# LPC12D27 register map
File version: 3
Registers are 32-bit, read-write, reset 0x0 unless marked. A register's access mark holds for its fields unless they carry their own. Offsets are from the block's base; [hi:lo] are bit positions; {n}, {i} and the like mark numbered series; 'fields as' and 'values as' point back to an identical list.

## RTC — Product name title=UM10441 Chapter title=LPC122x Real-Time Clock (RTC) Modification date=2/11/2011 Major revision=1 Minor revision=0
Base 0x40050000
0x00 DR ro — Data register
  [31:0] DATA — Returns the current RTC value.
0x04 MR — Match register
  [31:0] MATCH — RTC match register value.
0x08 LR — Load register
  [31:0] LOAD — RTC load register value.
0x0C CR — Control register
  [0] RTCSTART — Enables the RTC. Once the RTC is enabled through this bit, any writes to this bit have no effect on the RTC until a system reset.
    0=RTC_DISABLED_; 1=RTC_ENABLED_
0x10 ICSC — Interrupt control set/clear register
  [0] RTCIC — Interrupt control register. A read returns the current value of the RTC control register.
    0=MASK (Writing 0 masks the interrupt.); 1=ENABLE (Writing 1 enables the interrupt.)
0x14 RIS ro — Raw interrupt status register
  [0] RTCRIS — Raw interrupt event flag register. A read returns the state of the raw interrupt event flag.
0x18 MIS ro — Masked interrupt status register
  [0] RTCMIS — Masked interrupt register status. A read returns the masked interrupt status as controlled by the ICR register.
0x1C ICR wo — Interrupt clear register
  [0] RTCICR — Raw interrupt event flag clear register. Writing one clears the interrupt event flag. Writing 0 has no effect.

## ACOMP — Product name title=UM10441 Chapter title=LPC122x Comparator Modification date=2/11/2011 Major revision=0 Minor revision=17
Base 0x40054000
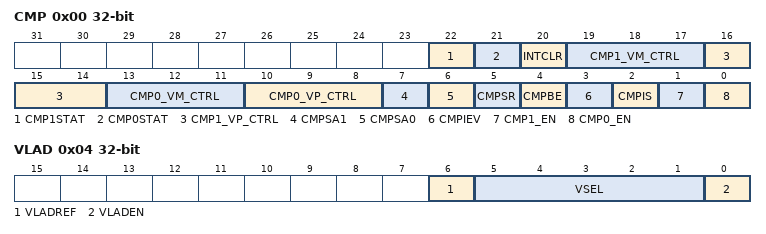
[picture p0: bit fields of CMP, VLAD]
0x00 CMP — Comparator control register
  [22] CMP1STAT — Comparator 1 status. This bit reflects the state of the comparator 1 output.
  [21] CMP0STAT — Comparator 0 status. This bit reflects the state of the comparator 0 output.
  [20] INTCLR — Interrupt clear bit. Setting this bit to one clears the comparator interrupt.
  [19:17] CMP1_VM_CTRL — Selection of comparator 1, negative voltage (VM) input channel.
    0=VOLTAGE_LADDER_OUTPU (Voltage ladder output); {v}=ACMP1_I{v-1} (v=1..4); 5=ACMP0_I0; 6=ACMP0_I1; 7=BOD_0_9_V_BAND_GAP
  [16:14] CMP1_VP_CTRL — Selection of comparator 1, positive voltage (VP) input channel.
    values as CMP1_VM_CTRL
  [13:11] CMP0_VM_CTRL — Selection of comparator 0, negative voltage (VM) input channel.
    0=VOLTAGE_LADDER_OUTPU (Voltage ladder output); {v}=ACMP0_I{v-1} (v=1..4); 5=ACMP1_I0; 6=ACMP1_I1; 7=BOD_0_9_V_BAND_GAP
  [10:8] CMP0_VP_CTRL — Selection of comparator 0, positive voltage (VP) input channel.
    values as CMP0_VM_CTRL
  [7] CMPSA1 — Select async/sync output of the comparator 1.
    0=DIRECT (The comparator output is used directly.); 1=SYNCH (The comparator output is synchronized with the bus clock for output to other modules.)
  [6] CMPSA0 — Select async/sync output of the comparator 0.
    values as CMPSA1
  [5] CMPSR — Select orientation of the two comparators in the relaxation oscillator circuit.
  [4] CMPBE — Select edge triggered interrupt to be active on both edges.
    0=NOTBOTHEDGES (Interrupt not active on both edges.); 1=BOTHEDGES (Interrupt active on both edges.)
  [3] CMPIEV — Select edge triggered interrupt to be active on either high or low transitions.
    0=FALLING (Interrupt active on falling edges.); 1=RISING (Interrupt active on rising edges.)
  [2] CMPIS — Select interrupt source.
    0=EDGE_TRIGGERED_; 1=LEVEL_TRIGGERED_
  [1] CMP1_EN — Comparator 1 enable.
    0=COMPARATOR_1_DISABLE (Comparator 1 disabled.); 1=COMPARATOR_1_ENABLED
  [0] CMP0_EN — Comparator 0 enable.
    0=COMPARATOR_0_DISABLE (Comparator 0 disabled.); 1=COMPARATOR_0_ENABLED
0x04 VLAD — Voltage ladder register
  [6] VLADREF — Voltage reference select
    0=VREF_CMP_PIN; 1=VDD3V3_PIN
  [5:1] VSEL — Voltage ladder value. The reference voltage Vref depends on the setting of bit 6 in this register (either V DD(3V3) or voltage on pin VREF_CMP): 0000 = VSS 0001 = 1 x Vref/31 0010 = 2 x Vref/31 ... 11111 = Vref
  [0] VLADEN — Voltage ladder enable
    0=VOLTAGE_LADDER_DISAB (Voltage ladder disabled.); 1=VOLTAGE_LADDER_ENABL (Voltage ladder enabled.)
